# DDR0_CTLPHY_WRAP_PHY_CFG register map
Vendor: Texas Instruments
Registers are 32-bit, access per field, reset 0x0 unless marked. A register's access mark holds for its fields unless they carry their own. Offsets are as the file gives them; [hi:lo] are bit positions; {n}, {i} and the like mark numbered series; 'fields as' and 'values as' point back to an identical list.

## DDR0_CTLPHY_WRAP_PHY_CFG (part 4 of 4)
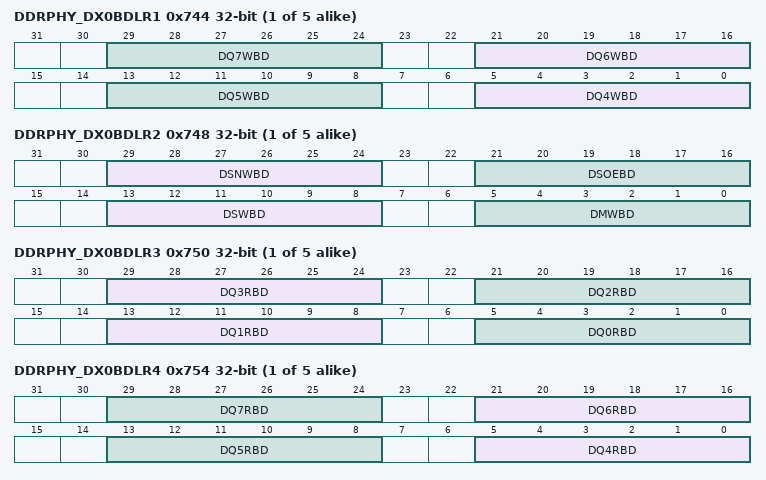
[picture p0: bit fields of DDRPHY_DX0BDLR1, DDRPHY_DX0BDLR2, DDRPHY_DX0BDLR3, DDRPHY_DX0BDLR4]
{0x744+0x100*i} DDRPHY_DX{i}BDLR1 (i=0..4) — DATX8 n Bit Delay Line Register 1
  [8n-27:8n-32] DQ{n}WBD rw (n=4..7) — DQ{n} Write Bit Delay: Delay select for the BDL on DQ{n} write path.
{0x748+0x100*i} DDRPHY_DX{i}BDLR2 (i=0..4) — DATX8 n Bit Delay Line Register 2
  [29:24] DSNWBD rw — DQSN Write Bit Delay: Delay select for the BDL on DQSN write path
  [21:16] DSOEBD rw — DQS/DM/DQ Output Enable Bit Delay: Delay select for the BDL.
  [13:8] DSWBD rw — DQS Write Bit Delay: Delay select for the BDL on DQS write path
  [5:0] DMWBD rw — DM Write Bit Delay: Delay select for the BDL on DM write path.
{0x750+0x100*i} DDRPHY_DX{i}BDLR3 (i=0..4) — DATX8 n Bit Delay Line Register 3
  [29:24] DQ3RBD rw — DQ3 Read Bit Delay: Delay select for the BDL on DQ3 read path
  [21:16] DQ2RBD rw — DQ2 Read Bit Delay: Delay select for the BDL on DQ2 read path.
  [13:8] DQ1RBD rw — DQ1 Read Bit Delay: Delay select for the BDL on DQ1 read path.
  [5:0] DQ0RBD rw — DQ0 Read Bit Delay: Delay select for the BDL on DQ0 read path.
{0x754+0x100*i} DDRPHY_DX{i}BDLR4 (i=0..4) — DATX8 n Bit Delay Line Register 4
  [8n-27:8n-32] DQ{n}RBD rw (n=4..7) — DQ{n} Read Bit Delay: Delay select for the BDL on DQ{n} read path.
{0x758+0x100*i} DDRPHY_DX{i}BDLR5 (i=0..4) — DATX8 n Bit Delay Line Register 5
  [5:0] DMRBD rw — DM Read Bit Delay: Delay select for the BDL on DM read path.
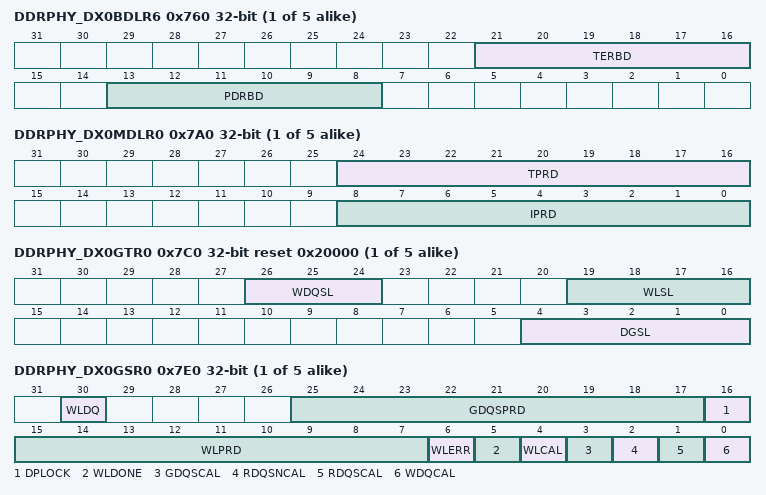
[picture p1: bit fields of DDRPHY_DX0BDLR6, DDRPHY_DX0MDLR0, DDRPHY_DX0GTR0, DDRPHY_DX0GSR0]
{0x760+0x100*i} DDRPHY_DX{i}BDLR6 (i=0..4) — DATX8 n Bit Delay Line Register 6
  [21:16] TERBD rw — Termination Enable Bit Delay: Delay select for the BDL.
  [13:8] PDRBD rw — Power down receiver Bit Delay: Delay select for the BDL.
{0x780+0x100*i} DDRPHY_DX{i}LCDLR0 (i=0..4) — DATX8 n Local Calibrated Delay Line Register 0
  [8:0] WLD rw — Write Leveling Delay: Delay select for the write leveling (WL) LCDL. This register is updated by hardware during write leveling.
{0x784+0x100*i} DDRPHY_DX{i}LCDLR1 (i=0..4) — DATX8 n Local Calibrated Delay Line Register 1
  [8:0] WDQD rw — Write Data Delay
{0x788+0x100*i} DDRPHY_DX{i}LCDLR2 (i=0..4) — DATX8 n Local Calibrated Delay Line Register 2
  [8:0] DQSGD rw — DQS Gating Delay: Delay select for the DQS gating (DQSG) LCDL This field is updated by hardware during:
{0x78C+0x100*i} DDRPHY_DX{i}LCDLR3 (i=0..4) — DATX8 n Local Calibrated Delay Line Register 3
  [8:0] RDQSD rw — Read DQS Delay: Delay select for the read DQS (RDQS) LCDL. This field is updated by hardware in the following cases:
{0x790+0x100*i} DDRPHY_DX{i}LCDLR4 (i=0..4) — DATX8 n Local Calibrated Delay Line Register 4
  [8:0] RDQSND rw — Read DQSN Delay: Delay select for the read DQSN (RDQSN) LCDL. This field is updated by hardware in the following cases:
{0x794+0x100*i} DDRPHY_DX{i}LCDLR5 (i=0..4) — DATX8 n Local Calibrated Delay Line Register 5
  [8:0] DQSGSD rw — DQS Gate Status Delay: Delay select for the DQS gate status (DQSGS) LCDL.
{0x7A0+0x100*i} DDRPHY_DX{i}MDLR0 (i=0..4) — DATX8 n Master Delay Line Register 0
  [24:16] TPRD rw — Target Period: Target period measured by the master delay line calibration for VT drift compensation. This is the current measured value of the period and is continuously updated if the MDL is enabled to do so.
  [8:0] IPRD rw — Initial Period: Initial period measured by the master delay line calibration for VT drift compensation. This value is used as the denominator when calculating the ratios of updates during VT compensation.
{0x7A4+0x100*i} DDRPHY_DX{i}MDLR1 (i=0..4) — DATX8 n Master Delay Line Register 1
  [8:0] MDLD rw — MDL Delay: Delay select for the LCDL for the Master Delay Line.
{0x7C0+0x100*i} DDRPHY_DX{i}GTR0 reset 0x20000 (i=0..4) — DATX8 n General Timing Register 0
  [26:24] WDQSL rw — DQ write path latency pipeline: Write data is pipelined by (WLSL + WDQSL). Total write data pipeline is: [Write leveling system latency] + WDQSL/2 DRAM clock periods This value is adjusted by LPDDR4 tDQS2DQ training and write eye centering. Any update in DDRPHY_DXnLCDLR1[WDQD] will update this field after 20 DDRSS_PHY_CTL_CLK clock cycles. Reading this field shows the number of pipelines (UI delays) written into DDRPHY_DXnLCDLR1[WDQD] field. Make sure content of this register field is not overwritten by the software.
  [19:16] WLSL rw — Write Leveling System Latency: Used to adjust the write latency after write leveling. This field is for the byte when in x8 mode Valid values:
  [4:0] DGSL rw — DQS Gating System Latency: This is used to increase the number of clock cycles needed to expect valid DDR read data. This is used to compensate for board delays and other system delays. Power-up default is 0x00 (i.e. no extra clock cycles required). Valid values are 0 to 18 and each increment adds a half SDRAM CK period.
{0x7D0+0x100*i} DDRPHY_DX{i}RSR0 ro (i=0..4) — DATX8 n Rank Status Register 0
  [15:0] QSGERR — DQS Gate Training Error: Indicates if set that there is an error in DQS gate training of the byte in x8 mode One bit for each of the up to 16 ranks.
{0x7D4+0x100*i} DDRPHY_DX{i}RSR1 ro (i=0..4) — DATX8 n Rank Status Register 1
  [15:0] RDLVLERR — Read Leveling Error: Indicates, if set, that there is an error in read leveling training of the byte in x8 mode One bit for each of the up to 16 ranks.
{0x7D8+0x100*i} DDRPHY_DX{i}RSR2 ro (i=0..4) — DATX8 n Rank Status Register 2
  [15:0] WLAWN — Write Latency Adjustment “DQS off on some DQ lines” warning. One bit per rank indicates that, for that rank, the WLA algorithm found some DQ lines where the read data sequence did not match the expected comparison signatures. This is for the byte in x8 mode
{0x7DC+0x100*i} DDRPHY_DX{i}RSR3 ro (i=0..4) — DATX8 n Rank Status Register 3
  [15:0] WLAERR — Write Latency Adjustment error: Indicates, for each of the system ranks, that an error occurred in the WLA algorithm. This is for the byte in x8 mode
{0x7E0+0x100*i} DDRPHY_DX{i}GSR0 ro (i=0..4) — DATX8 n General Status Register 0
  [30] WLDQ — Write Leveling DQ Status: Captures the write leveling DQ status from the DRAM during software write leveling.
  [25:17] GDQSPRD — Read DQS gating Period: Returns the DDR clock period measured by the read DQS gating LCDL during calibration. This value is PVT compensated.
  [16] DPLOCK — DATX8 PLL Lock: Indicates, if set, that DATX8 PLL has locked. This is a direct status of the DATX8 PLL lock pin.
  [15:7] WLPRD — Write Leveling Period: Returns the DDR clock period measured by the write leveling LCDL during calibration. The measured period is used to generate the control of the write leveling pipeline which is a function of the write-leveling delay and the clock period. This value is PVT compensated.
  [6] WLERR — Write Leveling Error: Indicates, if set, that there is a write leveling error in the DATX8.
  [5] WLDONE — Write Leveling Done: Indicates, if set, that the DATX8 has completed write leveling.
  [4] WLCAL — Write Leveling Calibration: Indicates, if set, that the DATX8 has finished doing period measurement calibration for the write leveling slave delay line.
  [3] GDQSCAL — Read DQS gating Calibration: Indicates, if set, that the DATX8 has finished doing period measurement calibration for the read DQS gating LCDL.
  [2] RDQSNCAL — Read DQS# Calibration: Indicates, if set, that the DATX8 has finished doing period measurement calibration for the read DQS# LCDL.
  [1] RDQSCAL — Read DQS Calibration: Indicates, if set, that the DATX8 has finished doing period measurement calibration for the read DQS LCDL.
  [0] WDQCAL — Write DQ Calibration: Indicates, if set, that the DATX8 has finished doing period measurement calibration for the write DQ LCDL.
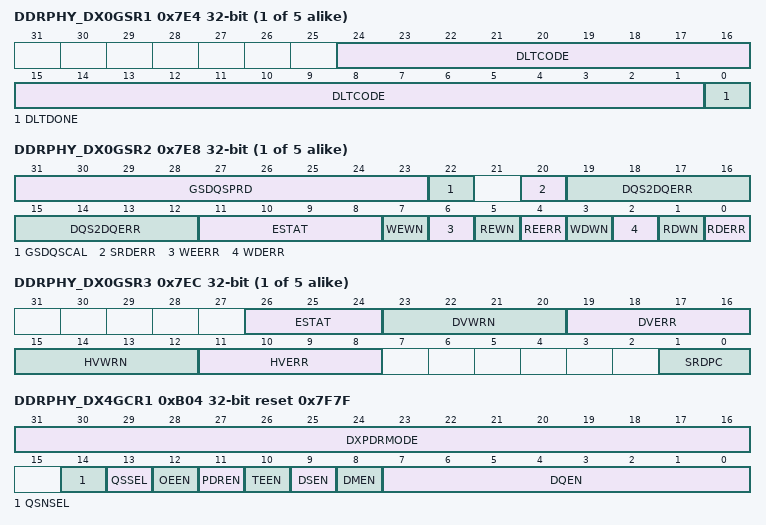
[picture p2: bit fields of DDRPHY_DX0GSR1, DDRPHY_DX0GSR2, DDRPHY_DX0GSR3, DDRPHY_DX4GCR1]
{0x7E4+0x100*i} DDRPHY_DX{i}GSR1 ro (i=0..4) — DATX8 n General Status Register 1
  [24:1] DLTCODE — Delay Line Test Code: Returns the code measured by the PHY control block that corresponds to the period of the DATX8 delay line digital test output.
  [0] DLTDONE — Delay Line Test Done: Indicates, if set, that the PHY control block has finished doing period measurement of the DATX8 delay line digital test output.
{0x7E8+0x100*i} DDRPHY_DX{i}GSR2 ro (i=0..4) — DATX8 n General Status Register 2
  [31:23] GSDQSPRD — Read DQS gating Status Period: Returns the DDR clock period measured by the read DQS gating status LCDL during calibration. This value is PVT compensated.
  [22] GSDQSCAL — Read DQS Gating Status Calibration: Indicates, if set, that the DATX8 has finished doing period measurement calibration for the read DQS gating status LCDL.
  [20] SRDERR — Static Read Error: Indicates, if set, that the DATX8 has encountered an error during execution of the static read training. Static read training not supported in this release.
  [19:12] DQS2DQERR — Write DQS2DQ training error: Indicates, if set, that the DATX8 has encountered an error during execution of the write DQS2DQ training Each 2 bits indicate error on one rank. (e.g. bits [13:12] shows error on rank 0) Status encoding are:
  [11:8] ESTAT — Error Status: If an error occurred for this lane as indicated by RDERR, WDERR, REERR or WEERR the error status code can provide additional information regard when the error occurred during the algorithm execution.
  [7] WEWN — Write Eye Centering Warning: Indicates, if set, that the DATX8 has encountered a warning during execution of the write eye centering training.
  [6] WEERR — Write Eye Centering Error: Indicates, if set, that the DATX8 has encountered an error during execution of the write eye centering training.
  [5] REWN — Read Eye Centering Warning: Indicates, if set, that the DATX8 has encountered a warning during execution of the read eye centering training.
  [4] REERR — Read Eye Centering Error: Indicates, if set, that the DATX8 has encountered an error during execution of the read eye centering training.
  [3] WDWN — Write Bit Deskew Warning: Indicates, if set, that the DATX8 has encountered a warning during execution of the write bit deskew training.
  [2] WDERR — Write Bit Deskew Error: Indicates, if set, that the DATX8 has encountered an error during execution of the write bit deskew training.
  [1] RDWN — Read Bit Deskew Warning: Indicates, if set, that the DATX8 has encountered a warning during execution of the read bit deskew training.
  [0] RDERR — Read Bit Deskew Error: Indicates, if set, that the DATX8 has encountered an error during execution of the read bit deskew training.
{0x7EC+0x100*i} DDRPHY_DX{i}GSR3 ro (i=0..4) — DATX8 n General Status Register 3
  [26:24] ESTAT — VREF Training Error Status Code: Indicates which phase of error check failed. Valid status encodings are: ESTAT[0] = Init vref check failed. ESTAT[1] = Final check for DRAM VREF failed ESTAT[2] = Final check for Host VREF failed.
  [23:20] DVWRN — DRAM VREF Training Warning: Indicates if set that there an warning in VREF was Training. Each bit indicates error for one rank.
  [19:16] DVERR — DRAM VREF Training Error: Indicates if set that there an error in VREF was Training. Each bit indicates error for one rank.
  [15:12] HVWRN — Host VREF Training Warning: Indicates if set that there an warning in VREF was Training. Each bit indicates error for one rank.
  [11:8] HVERR — Host VREF Training Error: Indicates if set that there an error in VREF was Training. Each bit indicates error for one rank.
  [1:0] SRDPC — Static Read Delay Pass Count: This read only field provides information regarding the trained RDDLY value in DDRPHY_DXnGCR0[23:20]. Valid status encodings are:
{0x7F0+0x100*i} DDRPHY_DX{i}GSR4 ro (i=0..4) — DATX8 n General Status Register 4
{0x7F4+0x100*i} DDRPHY_DX{i}GSR5 ro (i=0..4) — DATX8 n General Status Register 5
{0x7F8+0x100*i} DDRPHY_DX{i}GSR6 ro (i=0..4) — DATX8 n General Status Register 6
  [31:24] DBDQ — Capture DB DQ[7:0], bits [31:28] is for DQ[7:4] for upper nibble, bits [27:24] is for DQ[3:0] for lower nibble. This Register bits is used for software based LPDDR3 CA training and Software based LPDDR4 Command Bus Training.
0xB04 DDRPHY_DX4GCR1 reset 0x7F7F — DATX8 n General Configuration Register 1
  [31:16] DXPDRMODE rw — Enables the PDR mode values for DQ[7:0]. The bit [1:0] is for DQ[0], bit[3:2] for DQ[1] etc. Valid values are:
  [14] QSNSEL rw — Selects the delayed or non-delayed read data strobe #
  [13] QSSEL rw — Selects the delayed or non-delayed read data strobe
  [12] OEEN rw — Output Enable Clock Gate: When set to 0, this signal will gate (stop) the clocks to all registers inside the I/O output enable (D) slice
  [11] PDREN rw — I/O Power-Down Receiver Clock Gate: When set to 0, this signal will gate (stop) the clocks to all registers inside the I/O power-down receiver (D) slice.
  [10] TEEN rw — I/O Terminate Enable Clock Gate: When set to 0, this signal will gate (stop) the clocks to all registers inside the I/O terminate enable (D) slice.
  [9] DSEN rw — Data Strobe, Data Strobe # , Read Data Valid, Read Data Strobe , Read Data Strobe Gate , Control Clock Gate and Clock Generator Clock Gate: When set to 0, this signal will gate (stop) the clocks to all registers inside the corresponding block. Read Data Strobe, Read Data Strobe#, Read Data Strobe gate Enable: Enables, when set to 1
  [8] DMEN rw — Data Mask Clock Gate: When set to 0, this signal will gate (stop) the clock to all registers inside a correspondingly numbered data output (D) slice. Read Data Mask Clock Gate: When set to 0, this signal will gate (stop) the clock to all registers inside a correspondingly numbered read data input (Q) slice. Read Data Mask Enable: Enables, if set to 1, the read data path.
  [7:0] DQEN rw — Enables DQ corresponding to each bit in a byte
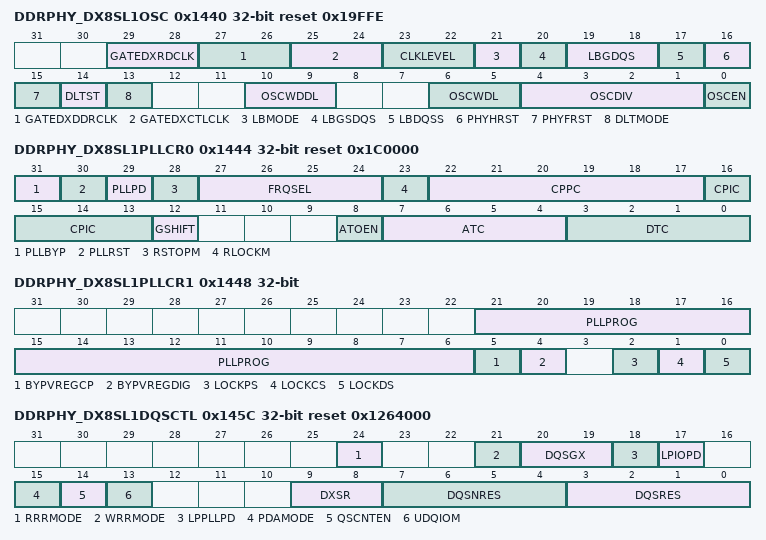
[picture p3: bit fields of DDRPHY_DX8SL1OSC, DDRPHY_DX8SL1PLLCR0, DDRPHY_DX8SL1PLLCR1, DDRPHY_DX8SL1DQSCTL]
0x1440 DDRPHY_DX8SL1OSC access not given reset 0x19FFE — DATX8 0-1 Oscillator, Delay Line Test, PHY FIFO and High Speed Reset, Loopback, and Gated Clock Control Register
  [29:28] GATEDXRDCLK rw — Enable Clock Gating for DX ctl_rd_clk: Enables, when set, clock gating for power saving. Valid values are: Valid values are:
  [27:26] GATEDXDDRCLK rw — Enable Clock Gating for DX DDRSS_BYP_4X_CLK: Enables, when set, clock gating for power saving. Valid values are:
  [25:24] GATEDXCTLCLK rw — Enable Clock Gating for DX DDRSS_PHY_CTL_CLK: Enables, when set, clock gating for power saving. Valid values are:
  [23:22] CLKLEVEL rw — Selects the level to which clocks will be stalled when clock gating is enabled in PHY. Valid values are:
  [21] LBMODE rw — Loopback Mode: Indicates, if set, that the PHY/PUB is in loopback mode.
  [20] LBGSDQS — Load GSDQS LCDL with 2x the calibrated GSDQSPRD value (equivalent to one CK period). This bit must only be used when initializing the GSDQS 180 degree offset for IO assisted gating mode. This bit is self clearing. (access RW1C)
  [19:18] LBGDQS rw — Loopback DQS Gating: Selects the DQS gating mode that should be used when the PHY is in loopback mode, including BIST loopback mode. Valid values are:
  [17] LBDQSS rw — Loopback DQS Shift: Selects how the read DQS is shifted during loopback to ensure that the read DQS is centered into the read data eye. Valid values are:
  [16] PHYHRST rw — PHY High-Speed Reset: A write of 1b0 to this bit resets the DATX8 macros without resetting PUB logic. This bit is not self-clearing and a 1b1 must be written to de-assert the reset.
  [15] PHYFRST rw — PHY FIFO Reset: A write of 1b0 to this bit resets the DATX8 FIFOs without resetting PUB logic. This bit is not self-clearing and a 1b1 must be written to de-assert the reset.
  [14] DLTST rw — Delay Line Test Start: A write of 1b1 to this bit will trigger delay line oscillator mode period measurement. This bit is not self clearing and needs to be reset to 1b0 before the measurement can be re-triggered.
  [13] DLTMODE rw — Delay Line Test Mode: Selects, if set, the delay line oscillator test mode.
  [10:9] OSCWDDL rw — Oscillator Mode Write-Data Delay Line Select: Selects which of the two write data (WDQ) LCDLs is active. The delay select value of the inactive LCDL is set to zero while the delay select value of the active LCDL can be varied by the input write leveling delay select pin. Valid values are:
  [6:5] OSCWDL rw — Oscillator Mode Write-Leveling Delay Line Select: Selects which of the two write leveling LCDLs is active. The delay select value of the inactive LCDL is set to zero while the delay select value of the active LCDL can be varied by the input write leveling delay select pin. Valid values are:
  [4:1] OSCDIV rw — Oscillator Mode Division: Specifies the factor by which the delay line oscillator mode output is divided down before it is output on the delay line digital test output pin dl_dto. Valid values are:
  [0] OSCEN rw — Oscillator Enable: Enables, if set, the delay line oscillation.
0x1444 DDRPHY_DX8SL1PLLCR0 reset 0x1C0000 — DAXT8 0-1 PLL Control Register 0
  [31] PLLBYP rw — PLL Bypass: Bypasses the PLL if set to 1b1.
  [30] PLLRST rw — PLL Reset: Resets the PLLs by driving the PLL reset pin. This bit is not self-clearing and a 1b0 must be written to de-assert the reset.
  [29] PLLPD rw — PLL Power Down: Puts the PLLs in power down mode by driving the PLL power down pin. This bit is not self-clearing and a 1b0 must be written to de-assert the power-down.
  [28] RSTOPM rw — Reference Stop Mode. Connects to pin REF_STOP_MODE. Valid values are:
  [27:24] FRQSEL rw — PLL Frequency Select: Selects the operating range of the PLL. Settings are specific to PLL type.
  [23] RLOCKM rw — Relock Mode: Enables, if set, rapid relocking mode.
  [22:17] CPPC rw — Charge Pump Proportional Current Control. Connects to pin CPPROP_CTRL on the PLL. Valid values are:
  [16:13] CPIC rw — Charge Pump Integrating Current Control. Connects to pin CP_INT_CTRL on the PLL. Valid values are:
  [12] GSHIFT rw — Gear Shift: Enables, if set, rapid locking mode. Connects to pin GEAR_SHIFT on the PLL.
  [8] ATOEN rw — Analog Test Enable (ATOEN): Selects the analog test signal that should be driven on the analog test output pin. Otherwise the analog test output is tri-stated. This allows analog test output pins from multiple PLLs to be connected together. Valid values are:
  [7:4] ATC rw — Analog Test Control: Controls PLL input pins pll_ana_test_sel[3:0]. Selects various PLL analog test signals to be brought out via PLL analog test output pin (pll_ato).
  [3:0] DTC rw — Digital Test Control: Controls PLL input pins pll_dig_test_sel. Selects various PLL digital test signals and other test mode signals to be brought out via bit [1] of the PLL digital test output (pll_dto[1]).
0x1448 DDRPHY_DX8SL1PLLCR1 — DAXT8 0-1 PLL Control Register 1 (Type B PLL Only)
  [21:6] PLLPROG rw — Connects to the PLL PLL_PROG bus.
  [5] BYPVREGCP rw — Bypass PLL vreg_cp
  [4] BYPVREGDIG rw — Bypass PLL vreg_dig.
  [2] LOCKPS rw — Lock Detector Phase Select. Connects to pin LOCK_PHASE_SEL on the PLL.
  [1] LOCKCS rw — Lock Detector Counter Select. Connects to pin LOCK_COUNT_SEL on the PLL.
  [0] LOCKDS rw — Lock Detector Select. Connects to pin LOCK_DET_SEL on the PLL on the PLL.
{0x1444+4i} DDRPHY_DX8SL1PLLCR{i} rw (i=2..4) — DAXT8 0-1 PLL Control Register {i} (Type B PLL Only)
  [31:0] PLLCTRL_{32i-33}_{32i-64} — Connects to bits [{32i-33}:{32i-64}] of the PLL general control bus PLL_CTRL.
0x1458 DDRPHY_DX8SL1PLLCR5 — DAXT8 0-1 PLL Control Register 5 (Type B PLL Only)
  [7:0] PLLCTRL_103_96 rw — Connects to bits [103:96] of the PLL general control bus PLL_CTRL.
0x145C DDRPHY_DX8SL1DQSCTL reset 0x1264000 — DATX8 0-1 DQS Control Register
  [24] RRRMODE rw — Read Path Rise-to-Rise Mode: Indicates if set that the PHY mission mode is configured to run in rise-to-rise mode for the read path. Otherwise, if not set, the PHY mission mode for the read path is running in rise-to-fall mode.
  [21] WRRMODE rw — Write Path Rise-to-Rise Mode: Indicates if set that the PHY mission mode is configured to run in rise-to-rise mode for the write path. Otherwise, if not set, the PHY mission mode for the write path is running in rise-to-fall mode.
  [20:19] DQSGX rw — DQS Gate Extension: Specifies if set that the read DQS gate will be extended. This should be set ONLY when used with DQS pull-down and DQSn pull-up (DDRPHY_DX8SLnDQSCTL[DQSRES]&gt;0000 and DDRPHY_DX8SLnDQSCTL[DQSNRES]&gt;0000) and only in systems with no DQS termination or mid-rail DQS termination. Valid values are:
  [18] LPPLLPD rw — Low Power PLL Power Down: Specifies if set that the PHY should respond to the DFI low power opportunity request and power down the PLL of the byte if the wakeup time request satisfies the LPWAKEUP_THRSH. LPWAKEUP_THRSH is the Minimum threshold value of tlp_wakeup required to make phy go into low power mode by powering down PLL. The value of the dfi_lp_wakeup signal at the time that the dfi_lp_data_req &amp; dfi_lp_ctrl_req signal is de-asserted sets the tlp_wakeup time. The value is in tems of number clock cycles.
  [17] LPIOPD rw — Low Power I/O Power Down: Specifies if set that the PHY should respond to the DFI low power opportunity request and power down the I/Os of the byte.
  [15] PDAMODE rw — Set PDA mode timing. If this bit is set by the MCTL, the DFI write commands are delayed by 2 SDRAM clock cycles, while at the same time the DQ data will be advanced with respect to the DQS. This allows the MCTL to satisfy the t_PDA_S timing requirement. This register field must be set in conjunction with DDRPHY_PGCR4[18] for PDA mode to be properly enabled/disabled.
  [14] QSCNTEN rw — QS Counter Enable. Enables, if set, the counting of DQS edges for automatic shut-off of DQS gate. If turned off, the gate is closed using the gate signal from the PUB.
  [13] UDQIOM rw — Unused DQ I/O Mode: Selects SSTL mode (when set to 1b0) or CMOS mode (when set to 1b1) of the I/O for unused DQ pins.
  [9:8] DXSR rw — Data Slew Rate: Selects slew rate of the I/O for DQ, DM, and DQS/DQS# pins of all DATX8 macros.
  [7:4] DQSNRES rw — DQS# Resistor: DQS_c glitch suppression resistor controls
  [3:0] DQSRES rw — DQS Resistor: DQS_t glitch suppression resistor controls
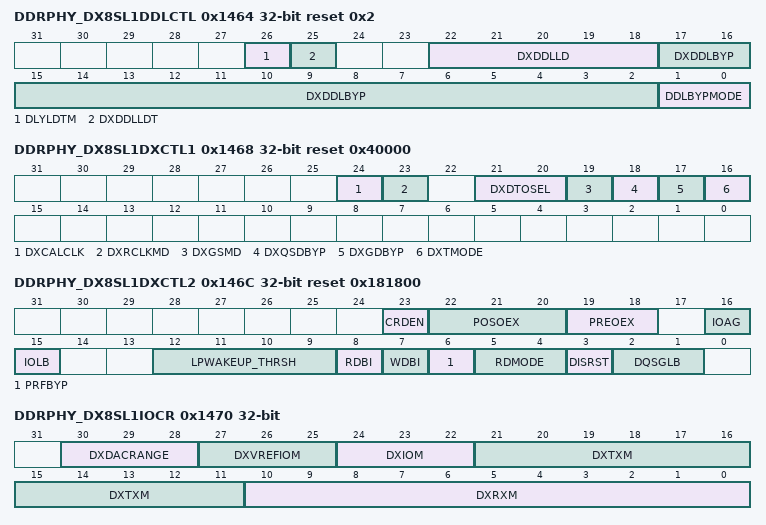
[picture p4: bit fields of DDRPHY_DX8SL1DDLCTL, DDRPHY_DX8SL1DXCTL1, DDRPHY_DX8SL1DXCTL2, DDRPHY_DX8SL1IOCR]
0x1464 DDRPHY_DX8SL1DDLCTL reset 0x2 — DATX8 0-1 DDL Control Register
  [26] DLYLDTM rw — Delay Load Timing: Specifies the timing of the signal that is used to load the new delay select values into the LCDL when switching between ranks that have different delays. Valid values are:
  [25] DXDDLLDT rw — DX DDL Load Type: Specifies how a new delay select value is applied to the delay line. This is only applicable to DDLs that have their delay select signals pipelined, such write leveling LCDL and read DQS gating LCDL. Valid values are:
  [22:18] DXDDLLD rw — DATX8 DDL Delay Select Dynamic Load: Specifies whether the registers inside the DATX8 that hold the delay select signal of DATX8 DDL should be dynamically loaded only when the delay select changes or should be continuously (always) loaded. Valid values are:
  [17:2] DXDDLBYP rw — DATX8 DDL Bypass: Specifies, if set to 1b1 that the DDL delay should be bypassed. Otherwise the DDL bypass is turned off. Different bits control different DATX8 DDLs as follows:
  [1:0] DDLBYPMODE rw — Controls DDL Bypass Mode
0x1468 DDRPHY_DX8SL1DXCTL1 reset 0x40000 — DATX8 0-1 DX Control Register 1
  [24] DXCALCLK rw — DATX Calibration Clock Select: Valid values are:
  [23] DXRCLKMD rw — DATX8 read Clock Mode: Valid values are:
  [21:20] DXDTOSEL rw — DATX8 Digital Test Output Select: This is used to select the DATX8 internal signals that should be driven on the two DATX8 digital test outputs (phy_status[3:2]) signals. Valid values for DATX8 digital test output bit 0 (phy_status[2]) are:Valid values for digital test out bit 1[1] (phy_status[3]) are:
  [19] DXGSMD rw — Read DQS gating status mode: Indicates if set that the read DQS gating status that is stored in the DQS read FIFO is the gate input. Otherwise, if not set, the registered DQS gate status is stores in the FIFO
  [18] DXQSDBYP rw — Read DQS/DQS# delay load bypass mode. Valid values are:
  [17] DXGDBYP rw — Read DQS gate delay load bypass mode. Valid values are:
  [16] DXTMODE rw — DATX8 Test Mode
0x146C DDRPHY_DX8SL1DXCTL2 reset 0x181800 — DATX8 0-1 DX Control Register 2
  [23] CRDEN rw — Configurable Read Data Enable:
  [22:20] POSOEX rw — OE extension during post-amble
  [19:18] PREOEX rw — OE extension during pre-amble
  [16] IOAG rw — I/O-assisted Gate Select (experimental read gate mode)
  [15] IOLB rw — DATX8 I/O Loop-Back Select: Selects where inside the I/O the loop-back of signals happens. Valid values are:
  [12:9] LPWAKEUP_THRSH rw — Low Power Wakeup Threshold: If dfi_lp_wakeup is greater than this threshold value, PLLs will be powered down when entering DFI low power mode. The value of the dfi_lp_wakeup signal at the time that the dfi_lp_ctrl_req or dfi_lp_data_req signal is asserted sets the tlp_wakeup time. Valid values in tems of number clock cycles are:
  [8] RDBI rw — Read Data Bus Inversion Enable: when set to 1b1 (and MR5[12] is set to 1b11b1 in DDR4 mode and MR3[6] is set to 1'b1 in LPDDR4 mode). PUB performs data bus inversion on the DRAM read data; when set to 1b0, the read data and DM_n/DBI_n signal are passed on to the controller as is.
  [7] WDBI rw — Write Data Bus Inversion Enable: when set to 1b1 (and MR5[11:10] is set to 2b10 in DDR4 and MR3[7] is set to 1'b1 in LPDDR4 mode), PUB generates the write DBI on the DM_n/DBI_n signal. Not supported with write CRC.
  [6] PRFBYP rw — Pub Read FIFO Bypass: When set to 1b1, the read capture FIFO inside PUB is bypassed. Valid values are:
  [5:4] RDMODE rw — DATX8 Receive FIFO Read Mode. Valid values are:
  [3] DISRST rw — Disables the Read FIFO reset: When set, read receive fifo can’t be reset from ctl_dx_rdfifo_rstn input. Valid values are:
  [2:1] DQSGLB rw — Read DQS Gate, DQS, DQS# I/O Loopback: Controls the loopback signal (LB) on the I/O that is used to drive the read DQS gate, DQS and DQS#. This also selects the type of gating used since it controls the signal driven on the DI output of this PDQSG I/O. Valid values are:
0x1470 DDRPHY_DX8SL1IOCR — DATX8 0-1 I/O Configuration Register
  [30:28] DXDACRANGE rw — PVREF_DAC REFSEL range select
  [27:25] DXVREFIOM rw — IOM bits for PVREF, PVREF_DAC and PVREFE cells in DX IO ring
  [24:22] DXIOM rw — I/O Mode: I/O Mode select
  [21:11] DXTXM rw — DX IO transmitter mode
  [10:0] DXRXM rw — DX IO receiver mode
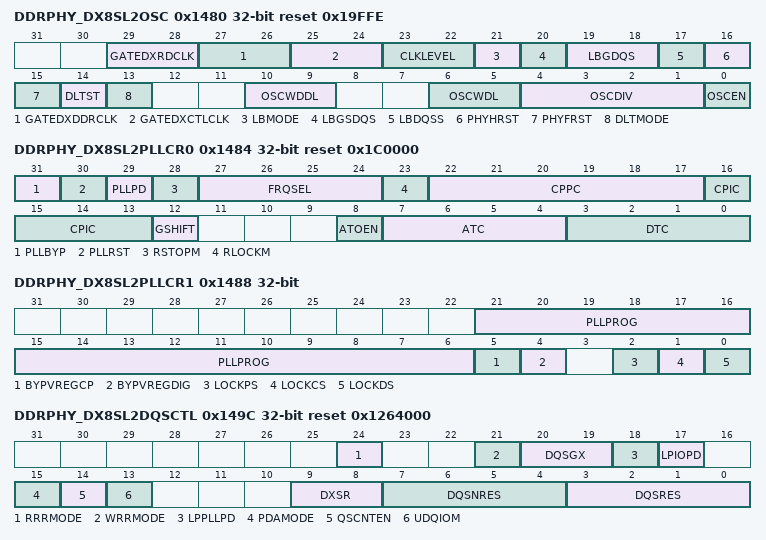
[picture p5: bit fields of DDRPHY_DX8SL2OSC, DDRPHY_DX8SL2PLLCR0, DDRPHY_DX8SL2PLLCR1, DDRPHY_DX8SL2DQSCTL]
0x1480 DDRPHY_DX8SL2OSC access not given reset 0x19FFE — DATX8 0-1 Oscillator, Delay Line Test, PHY FIFO and High Speed Reset, Loopback, and Gated Clock Control Register
  fields as DDRPHY_DX8SL1OSC
0x1484 DDRPHY_DX8SL2PLLCR0 reset 0x1C0000 — DAXT8 0-1 PLL Control Register 0
  fields as DDRPHY_DX8SL1PLLCR0
0x1488 DDRPHY_DX8SL2PLLCR1 — DAXT8 0-1 PLL Control Register 1 (Type B PLL Only)
  fields as DDRPHY_DX8SL1PLLCR1
{0x1484+4i} DDRPHY_DX8SL2PLLCR{i} rw (i=2..4) — DAXT8 0-1 PLL Control Register {i} (Type B PLL Only)
  fields as DDRPHY_DX8SL1PLLCR2
0x1498 DDRPHY_DX8SL2PLLCR5 — DAXT8 0-1 PLL Control Register 5 (Type B PLL Only)
  fields as DDRPHY_DX8SL1PLLCR5
0x149C DDRPHY_DX8SL2DQSCTL reset 0x1264000 — DATX8 0-1 DQS Control Register
  [24] RRRMODE rw — Read Path Rise-to-Rise Mode: Indicates if set that the PHY mission mode is configured to run in rise-to-rise mode for the read path. Otherwise, if not set, the PHY mission mode for the read path is running in rise-to-fall mode.
  [21] WRRMODE rw — Write Path Rise-to-Rise Mode: Indicates if set that the PHY mission mode is configured to run in rise-to-rise mode for the write path. Otherwise, if not set, the PHY mission mode for the write path is running in rise-to-fall mode.
  [20:19] DQSGX rw — DQS Gate Extension: Specifies if set that the read DQS gate will be extended. This should be set ONLY when used with DQS pull-down and DQSn pull-up (DDRPHY_DX8SLnDQSCTL[DQSRES]&gt;0000 and DDRPHY_DX8SLnDQSCTL[DQSNRES]&gt;0000) and only in systems with no DQS termination or mid-rail DQS termination. Valid values are:
  [18] LPPLLPD rw — Low Power PLL Power Down: Specifies if set that the PHY should respond to the DFI low power opportunity request and power down the PLL of the byte if the wakeup time request satisfies the LPWAKEUP_THRSH. LPWAKEUP_THRSH is the Minimum threshold value of tlp_wakeup required to make phy go into low power mode by powering down PLL. The value of the dfi_lp_wakeup signal at the time that the dfi_lp_data_req&amp;dfi_lp_ctrl_req signal is de-asserted sets the tlp_wakeup time. The value is in tems of number clock cycles.
  [17] LPIOPD rw — Low Power I/O Power Down: Specifies if set that the PHY should respond to the DFI low power opportunity request and power down the I/Os of the byte.
  [15] PDAMODE rw — Set PDA mode timing. If this bit is set by the MCTL, the DFI write commands are delayed by 2 SDRAM clock cycles, while at the same time the DQ data will be advanced with respect to the DQS. This allows the MCTL to satisfy the t_PDA_S timing requirement. This register field must be set in conjunction with DDRPHY_PGCR4[18] for PDA mode to be properly enabled/disabled.
  [14] QSCNTEN rw — QS Counter Enable. Enables, if set, the counting of DQS edges for automatic shut-off of DQS gate. If turned off, the gate is closed using the gate signal from the PUB.
  [13] UDQIOM rw — Unused DQ I/O Mode: Selects SSTL mode (when set to 1b0) or CMOS mode (when set to 1b1) of the I/O for unused DQ pins.
  [9:8] DXSR rw — Data Slew Rate: Selects slew rate of the I/O for DQ, DM, and DQS/DQS# pins of all DATX8 macros.
  [7:4] DQSNRES rw — DQS# Resistor: DQS_c glitch suppression resistor controls
  [3:0] DQSRES rw — DQS Resistor: DQS_t glitch suppression resistor controls
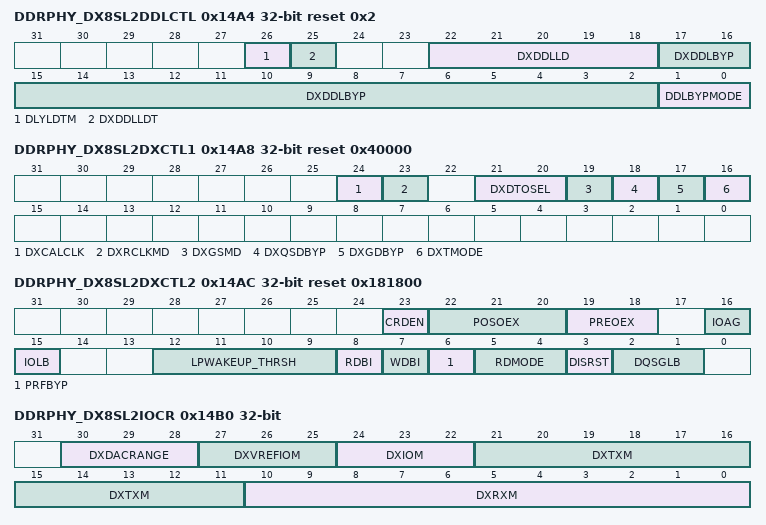
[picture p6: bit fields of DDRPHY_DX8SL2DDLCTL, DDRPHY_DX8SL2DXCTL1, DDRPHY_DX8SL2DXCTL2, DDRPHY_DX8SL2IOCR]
0x14A4 DDRPHY_DX8SL2DDLCTL reset 0x2 — DATX8 0-1 DDL Control Register
  fields as DDRPHY_DX8SL1DDLCTL
0x14A8 DDRPHY_DX8SL2DXCTL1 reset 0x40000 — DATX8 0-1 DX Control Register 1
  [24] DXCALCLK rw — DATX Calibration Clock Select: Valid values are:
  [23] DXRCLKMD rw — DATX8 read Clock Mode: Valid values are:
  [21:20] DXDTOSEL rw — DATX8 Digital Test Output Select: This is used to select the DATX8 internal signals that should be driven on the two DATX8 digital test outputs (phy_status[3:2]) signals. Valid values for DATX8 digital test output bit 0 (phy_status[2]) are:
  [19] DXGSMD rw — Read DQS gating status mode: Indicates if set that the read DQS gating status that is stored in the DQS read FIFO is the gate input. Otherwise, if not set, the registered DQS gate status is stores in the FIFO
  [18] DXQSDBYP rw — Read DQS/DQS# delay load bypass mode. Valid values are:
  [17] DXGDBYP rw — Read DQS gate delay load bypass mode. Valid values are:
  [16] DXTMODE rw — DATX8 Test Mode
0x14AC DDRPHY_DX8SL2DXCTL2 reset 0x181800 — DATX8 0-1 DX Control Register 2
  fields as DDRPHY_DX8SL1DXCTL2
0x14B0 DDRPHY_DX8SL2IOCR — DATX8 0-1 I/O Configuration Register
  fields as DDRPHY_DX8SL1IOCR
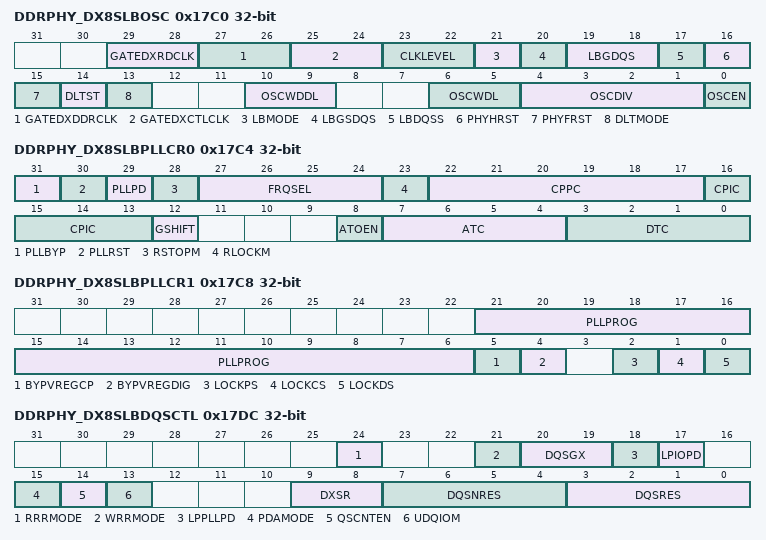
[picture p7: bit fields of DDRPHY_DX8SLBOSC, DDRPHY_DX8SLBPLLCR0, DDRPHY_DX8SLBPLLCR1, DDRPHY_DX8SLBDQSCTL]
0x17C0 DDRPHY_DX8SLBOSC wo — DATX8 0-8 Oscillator, Delay Line Test, PHY FIFO and High Speed Reset, Loopback, and Gated Clock Control Register
  [29:28] GATEDXRDCLK — Enable Clock Gating for DX ctl_rd_clk: Enables, when set, clock gating for power saving. Valid values are:
  [27:26] GATEDXDDRCLK — Enable Clock Gating for DX DDRSS_BYP_4X_CLK: Enables, when set, clock gating for power saving. Valid values are:
  [25:24] GATEDXCTLCLK — Enable Clock Gating for DX DDRSS_PHY_CTL_CLK: Enables, when set, clock gating for power saving. Valid values are:
  [23:22] CLKLEVEL — Selects the level to which clocks will be stalled when clock gating is enabled in PHY. Valid values are:
  [21] LBMODE — Loopback Mode: Indicates, if set, that the PHY/PUB is in loopback mode.
  [20] LBGSDQS — Load GSDQS LCDL with 2x the calibrated GSDQSPRD value (equivalent to one CK period). This bit must only be used when initializing the GSDQS 180 degree offset for IO assisted gating mode. This bit is self clearing.
  [19:18] LBGDQS — Loopback DQS Gating: Selects the DQS gating mode that should be used when the PHY is in loopback mode, including BIST loopback mode. Valid values are:
  [17] LBDQSS — Loopback DQS Shift: Selects how the read DQS is shifted during loopback to ensure that the read DQS is centered into the read data eye. Valid values are:
  [16] PHYHRST — PHY High-Speed Reset: A write of 1b0 to this bit resets the DATX8 macros without resetting PUB logic. This bit is not self-clearing and a 1b1 must be written to de-assert the reset.
  [15] PHYFRST — PHY FIFO Reset: A write of 1b0 to this bit resets the DATX8 FIFOs without resetting PUB logic. This bit is not self-clearing and a 1b1 must be written to de-assert the reset.
  [14] DLTST — Delay Line Test Start: A write of 1b1 to this bit will trigger delay line oscillator mode period measurement. This bit is not self clearing and needs to be reset to 1b0 before the measurement can be re-triggered.
  [13] DLTMODE — Delay Line Test Mode: Selects, if set, the delay line oscillator test mode.
  [10:9] OSCWDDL — Oscillator Mode Write-Data Delay Line Select: Selects which of the two write data (WDQ) LCDLs is active. The delay select value of the inactive LCDL is set to zero while the delay select value of the active LCDL can be varied by the input write leveling delay select pin. Valid values are:
  [6:5] OSCWDL — Oscillator Mode Write-Leveling Delay Line Select: Selects which of the two write leveling LCDLs is active. The delay select value of the inactive LCDL is set to zero while the delay select value of the active LCDL can be varied by the input write leveling delay select pin. Valid values are:
  [4:1] OSCDIV — Oscillator Mode Division: Specifies the factor by which the delay line oscillator mode output is divided down before it is output on the delay line digital test output pin dl_dto. Valid values are:
  [0] OSCEN — Oscillator Enable: Enables, if set, the delay line oscillation.
0x17C4 DDRPHY_DX8SLBPLLCR0 wo — DAXT8 0-8 PLL Control Register 0
  [31] PLLBYP — PLL Bypass: Bypasses the PLL if set to 1b1.
  [30] PLLRST — PLL Reset: Resets the PLLs by driving the PLL reset pin. This bit is not self-clearing and a 1b0 must be written to de-assert the reset.
  [29] PLLPD — PLL Power Down: Puts the PLLs in power down mode by driving the PLL power down pin. This bit is not self-clearing and a 1b0 must be written to de-assert the power-down.
  [28] RSTOPM — Reference Stop Mode. Connects to pin REF_STOP_MODE. Valid values are:
  [27:24] FRQSEL — PLL Frequency Select: Selects the operating range of the PLL. Settings are specific to PLL type.
  [23] RLOCKM — Relock Mode: Enables, if set, rapid relocking mode.
  [22:17] CPPC — Charge Pump Proportional Current Control. Connects to pin CPPROP_CTRL on the PLL. Valid values are:
  [16:13] CPIC — Charge Pump Integrating Current Control. Connects to pin CP_INT_CTRL on the PLL. Valid values are:
  [12] GSHIFT — Gear Shift: Enables, if set, rapid locking mode. Connects to pin GEAR_SHIFT on the PLL.
  [8] ATOEN — Analog Test Enable (ATOEN): Selects the analog test signal that should be driven on the analog test output pin. Otherwise the analog test output is tri-stated. This allows analog test output pins from multiple PLLs to be connected together. Valid values are:
  [7:4] ATC — Analog Test Control: Controls PLL input pins pll_ana_test_sel[3:0]. Selects various PLL analog test signals to be brought out via PLL analog test output pin (pll_ato).
  [3:0] DTC — Digital Test Control: Controls PLL input pins pll_dig_test_sel. Selects various PLL digital test signals and other test mode signals to be brought out via bit [1] of the PLL digital test output (pll_dto[1]).
0x17C8 DDRPHY_DX8SLBPLLCR1 wo — DAXT8 0-8 PLL Control Register 1 (Type B PLL Only)
  [21:6] PLLPROG — Connects to the PLL PLL_PROG bus.
  [5] BYPVREGCP — Bypass PLL vreg_cp
  [4] BYPVREGDIG — Bypass PLL vreg_dig.
  [2] LOCKPS — Lock Detector Phase Select. Connects to pin LOCK_PHASE_SEL on the PLL.
  [1] LOCKCS — Lock Detector Counter Select. Connects to pin LOCK_COUNT_SEL on the PLL.
  [0] LOCKDS — Lock Detector Select. Connects to pin LOCK_DET_SEL on the PLL on the PLL.
{0x17C4+4i} DDRPHY_DX8SLBPLLCR{i} wo (i=2..4) — DAXT8 0-8 PLL Control Register {i} (Type B PLL Only)
  fields as DDRPHY_DX8SL1PLLCR2
0x17D8 DDRPHY_DX8SLBPLLCR5 wo — DAXT8 0-8 PLL Control Register 5 (Type B PLL Only)
  [7:0] PLLCTRL_103_96 — Connects to bits [103:96] of the PLL general control bus PLL_CTRL.
0x17DC DDRPHY_DX8SLBDQSCTL wo — DATX8 0-8 DQS Control Register
  [24] RRRMODE — Read Path Rise-to-Rise Mode: Indicates if set that the PHY mission mode is configured to run in rise-to-rise mode for the read path. Otherwise, if not set, the PHY mission mode for the read path is running in rise-to-fall mode.
  [21] WRRMODE — Write Path Rise-to-Rise Mode: Indicates if set that the PHY mission mode is configured to run in rise-to-rise mode for the write path. Otherwise, if not set, the PHY mission mode for the write path is running in rise-to-fall mode.
  [20:19] DQSGX — DQS Gate Extension: Specifies if set that the read DQS gate will be extended. This should be set ONLY when used with DQS pull-down and DQSn pull-up. Valid values are:
  [18] LPPLLPD — Low Power PLL Power Down: Specifies if set that the PHY should respond to the DFI low power opportunity request and power down the PLL of the byte if the wakeup time request satisfies the LPWAKEUP_THRSH. LPWAKEUP_THRSH is the Minimum threshold value of tlp_wakeup required to make phy go into low power mode by powering down PLL. The value of the dfi_lp_wakeup signal at the time that the dfi_lp_data_req&amp;dfi_lp_ctrl_req signal is de-asserted sets the tlp_wakeup time. The value is in tems of number clock cycles.
  [17] LPIOPD — Low Power I/O Power Down: Specifies if set that the PHY should respond to the DFI low power opportunity request and power down the I/Os of the byte.
  [15] PDAMODE — Set PDA mode timing. If this bit is set by the MCTL, the DFI write commands are delayed by 2 SDRAM clock cycles, while at the same time the DQ data is advanced with respect to the DQS. This allows the MCTL to satisfy the t_PDA_S timing requirement. This register field must be set in conjunction with DDRPHY_PGCR4[18] for PDA mode to be properly enabled/disabled.
  [14] QSCNTEN — QS Counter Enable. Enables, if set, the counting of DQS edges for automatic shut-off of DQS gate. If turned off, the gate is closed using the gate signal from the PUB.
  [13] UDQIOM — Unused DQ I/O Mode: Selects SSTL mode (when set to 1b0) or CMOS mode (when set to 1b1) of the I/O for unused DQ pins.
  [9:8] DXSR — Data Slew Rate: Selects slew rate of the I/O for DQ, DM, and DQS/DQS# pins of all DATX8 macros.
  [7:4] DQSNRES — DQS# Resistor: DQS_c glitch suppression resistor controls
  [3:0] DQSRES — DQS Resistor: DQS_t glitch suppression resistor controls
0x17E0 DDRPHY_DX8SLBTRNCTL wo — DATX8 0-8 Training Control Register
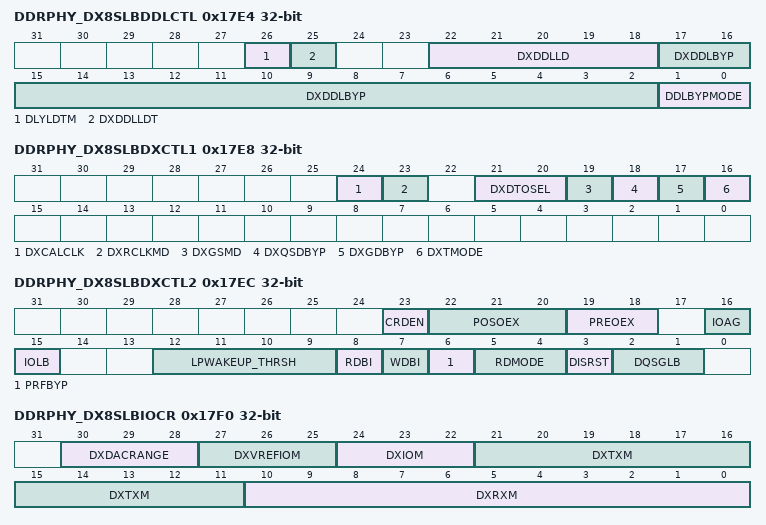
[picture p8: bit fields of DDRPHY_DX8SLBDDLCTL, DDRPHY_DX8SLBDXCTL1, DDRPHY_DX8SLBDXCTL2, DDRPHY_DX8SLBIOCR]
0x17E4 DDRPHY_DX8SLBDDLCTL wo — DATX8 0-8 DDL Control Register
  [26] DLYLDTM — Delay Load Timing: Specifies the timing of the signal that is used to load the new delay select values into the LCDL when switching between ranks that have different delays. Valid values are:
  [25] DXDDLLDT — DX DDL Load Type: Specifies how a new delay select value is applied to the delay line. This is only applicable to DDLs that have their delay select signals pipelined, such write leveling LCDL and read DQS gating LCDL. Valid values are:
  [22:18] DXDDLLD — DATX8 DDL Delay Select Dynamic Load: Specifies whether the registers inside the DATX8 that hold the delay select signal of DATX8 DDL should be dynamically loaded only when the delay select changes or should be continuously (always) loaded. Valid values are:
  [17:2] DXDDLBYP — DATX8 DDL Bypass: Specifies, if set to 1b1 that the DDL delay should be bypassed. Otherwise the DDL bypass is turned off. Different bits control different DATX8 DDLs as follows:
  [1:0] DDLBYPMODE — Controls DATX8 DDL Bypass Modes. Valid values are:
0x17E8 DDRPHY_DX8SLBDXCTL1 wo — DATX8 0-8 DX Control Register 1
  [24] DXCALCLK — DATX Calibration Clock Select: Valid values are:
  [23] DXRCLKMD — DATX8 read Clock Mode: Valid values are:
  [21:20] DXDTOSEL — DATX8 Digital Test Output Select: This is used to select the DATX8 internal signals that should be driven on the two DATX8 digital test outputs (phy_status[3:2]) signals. Valid values for DATX8 digital test output bit 0 (phy_status[2]) are:
  [19] DXGSMD — Read DQS gating status mode: Indicates if set that the read DQS gating status that is stored in the DQS read FIFO is the gate input. Otherwise, if not set, the registered DQS gate status is stores in the FIFO
  [18] DXQSDBYP — Read DQS/DQS# delay load bypass mode. Valid values are:
  [17] DXGDBYP — Read DQS gate delay load bypass mode. Valid values are:
  [16] DXTMODE — DATX8 Test Mode: This is used to enable special test mode in the DATX8 macro. Valid values are:
0x17EC DDRPHY_DX8SLBDXCTL2 wo — DATX8 0-8 DX Control Register 2
  [23] CRDEN — Configurable Read Data Enable:
  [22:20] POSOEX — OE extension during post-amble
  [19:18] PREOEX — OE extension during pre-amble
  [16] IOAG — I/O-assisted Gate Select (experimental read gate mode)
  [15] IOLB — I/O Loop-Back Select: Selects where inside the I/O the loop-back of signals happens. Valid values are:
  [12:9] LPWAKEUP_THRSH — Low Power Wakeup Threshold: If dfi_lp_wakeup is greater than this threshold value, PLLs will be powered down when entering DFI low power mode. The value of the dfi_lp_wakeup signal at the time that the dfi_lp_ctrl_req or dfi_lp_data_req signal is asserted sets the tlp_wakeup time. Valid values in tems of number clock cycles are:
  [8] RDBI — Read Data Bus Inversion Enable: when set to 1b1 (and MR5[12] is set 1b1 in DDR4 mode and MR3[6] is set to 1'b1 in LPDDR4 mode), PUB performs data bus inversion on the DRAM read data; when set to 1b0, the read data and DM_n/DBI_n signal are passed on to the controller as is.
  [7] WDBI — Write Data Bus Inversion Enable: when set to 1b1 (and MR5[11:10] is set to 2b10 in in DDR4 and MR3[7] is set to 1'b1 in LPDDR4 mode, PUB generates the write DBI on the DM_n/DBI_n signal. Not supported with write CRC.
  [6] PRFBYP — Pub Read FIFO Bypass: When set to 1b1, the read capture FIFO inside PUB is bypassed. Valid values are:
  [5:4] RDMODE — DATX8 Receive FIFO Read Mode. Valid values are:
  [3] DISRST — Disables the Read FIFO reset: When set, read receive fifo can’t be reset from ctl_dx_rdfifo_rstn input. Valid values are:
  [2:1] DQSGLB — Read DQS Gate, DQS, DQS# I/O Loopback: Controls the loopback signal (LB) on the I/O that is used to drive the read DQS gate, DQS and DQS#. This also selects the type of gating used since it controls the signal driven on the DI output of this PDQSG I/O. Valid values are:
0x17F0 DDRPHY_DX8SLBIOCR wo — DATX8 0-8 I/O Configuration Register
  [30:28] DXDACRANGE — PVREF_DAC REFSEL range select
  [27:25] DXVREFIOM — IOM bits for PVREF, PVREF_DAC and PVREFE cells in DX IO ring
  [24:22] DXIOM — I/O Mode: I/O Mode select
  [21:11] DXTXM — DX IO transmitter mode
  [10:0] DXRXM — DX IO receiver mode
0x17F4 DDRPHY_DX4SLBIOCR wo — DATX4 0-8 I/O Configuration Register
